# LCM32F039 register map
File version: 1.0
CPU: CM0 r1p0, little endian, MPU, no FPU, 3 interrupt priority bits
Registers are 32-bit, read-write, reset 0x0 unless marked. A register's access mark holds for its fields unless they carry their own. Offsets are from the block's base; [hi:lo] are bit positions; {n}, {i} and the like mark numbered series.

## EXTI
Base 0x40011000
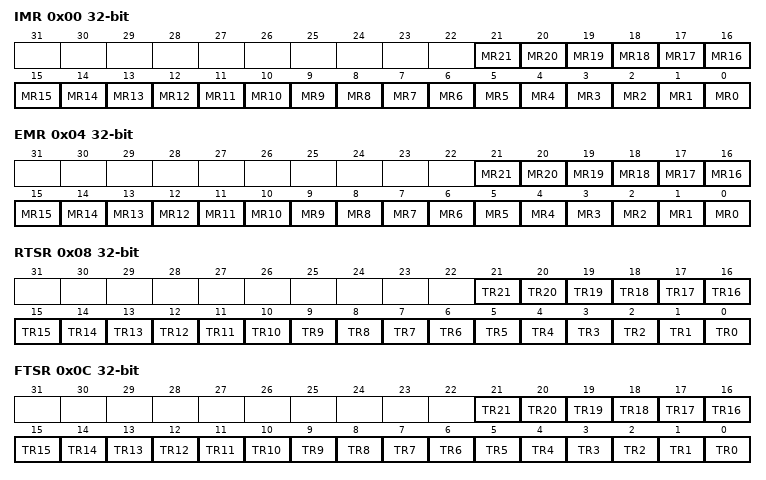
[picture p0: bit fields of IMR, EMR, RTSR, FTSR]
0x00 IMR — EXTI interrupt mask register
  [n] MR{n} (n=0..21) — Interrupt mask on external/internal line x
0x04 EMR — EXTI event mask register
  [n] MR{n} (n=0..21) — Event mask on external/internal line x
0x08 RTSR
  [n] TR{n} (n=0..21)
0x0C FTSR
  [n] TR{n} (n=0..21)
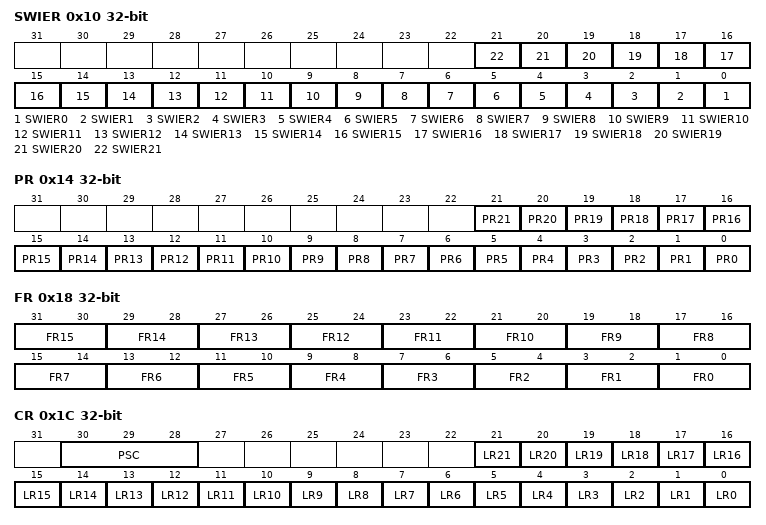
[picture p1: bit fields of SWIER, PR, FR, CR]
0x10 SWIER
  [n] SWIER{n} (n=0..21)
0x14 PR
  [n] PR{n} (n=0..21)
0x18 FR
  [2n+1:2n] FR{n} (n=0..15)
0x1C CR
  [30:28] PSC, [n] LR{n} (n=0..21)

## ANACTRL — Analog system controler.
Base 0x40017C00
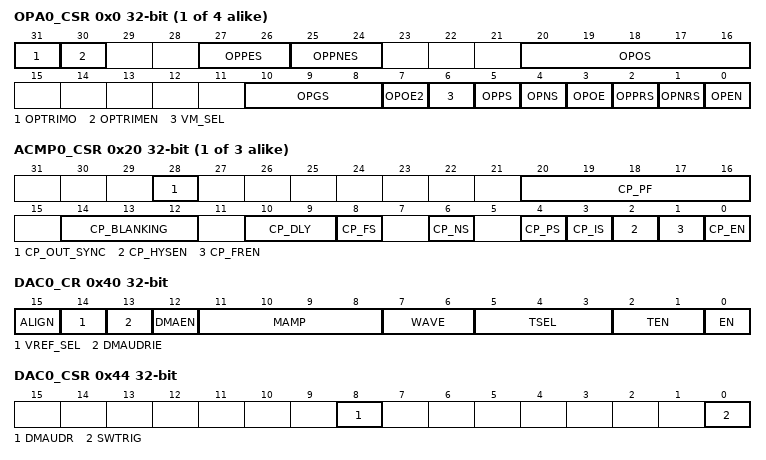
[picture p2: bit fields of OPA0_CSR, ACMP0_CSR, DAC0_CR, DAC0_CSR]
{0x0+4i} OPA{i}_CSR (i=0..3)
  [31] OPTRIMO, [30] OPTRIMEN, [27:26] OPPES, [25:24] OPPNES, [20:16] OPOS, [10:8] OPGS, [7] OPOE2, [6] VM_SEL, [5] OPPS, [4] OPNS, [3] OPOE, [2] OPPRS, [1] OPNRS, [0] OPEN
{0x20+4i} ACMP{i}_CSR (i=0..2)
  [28] CP_OUT_SYNC, [20:16] CP_PF, [14:12] CP_BLANKING, [10:9] CP_DLY, [8] CP_FS, [6] CP_NS, [4] CP_PS, [3] CP_IS, [2] CP_HYSEN, [1] CP_FREN, [0] CP_EN
0x40 DAC0_CR
  [15] ALIGN, [14] VREF_SEL, [13] DMAUDRIE, [12] DMAEN, [11:8] MAMP, [7:6] WAVE, [5:3] TSEL, [2:1] TEN, [0] EN
0x44 DAC0_CSR
  [8] DMAUDR, [0] SWTRIG
0x48 DAC0_DHR
  [15:0] DHR
0x4C DAC0_DOR ro
  [15:0] DOR
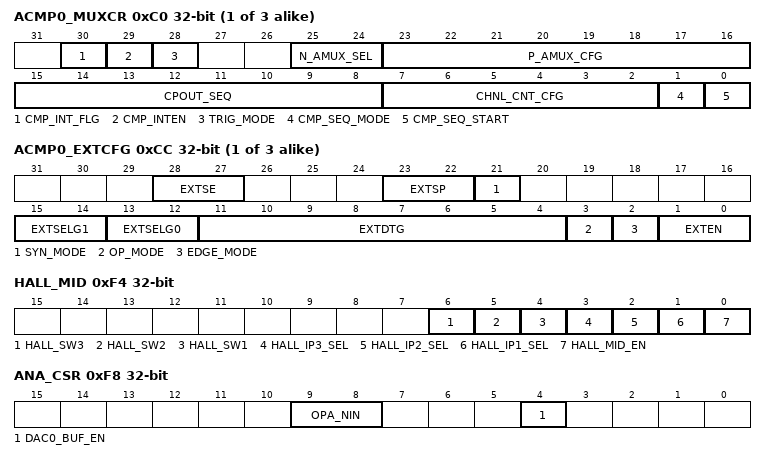
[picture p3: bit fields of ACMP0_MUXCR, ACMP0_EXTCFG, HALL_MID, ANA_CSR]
{0xC0+4i} ACMP{i}_MUXCR (i=0..2)
  [30] CMP_INT_FLG, [29] CMP_INTEN, [28] TRIG_MODE, [25:24] N_AMUX_SEL, [23:16] P_AMUX_CFG, [15:8] CPOUT_SEQ, [7:2] CHNL_CNT_CFG, [1] CMP_SEQ_MODE, [0] CMP_SEQ_START
{0xCC+4i} ACMP{i}_EXTCFG (i=0..2)
  [28:27] EXTSE, [23:22] EXTSP, [21] SYN_MODE, [15:14] EXTSELG1, [13:12] EXTSELG0, [11:4] EXTDTG, [3] OP_MODE, [2] EDGE_MODE, [1:0] EXTEN
0xF4 HALL_MID
  [6] HALL_SW3, [5] HALL_SW2, [4] HALL_SW1, [3] HALL_IP3_SEL, [2] HALL_IP2_SEL, [1] HALL_IP1_SEL, [0] HALL_MID_EN
0xF8 ANA_CSR
  [9:8] OPA_NIN, [4] DAC0_BUF_EN

## CHIPCTRL — chip controler moudle.
Base 0x40017000
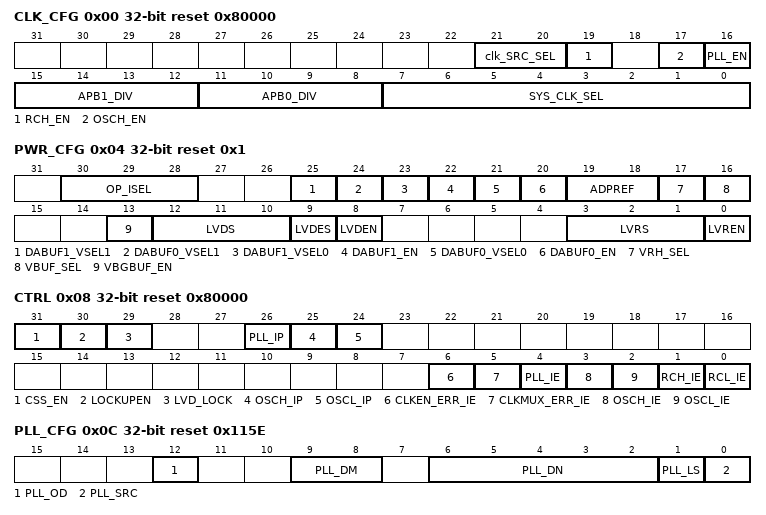
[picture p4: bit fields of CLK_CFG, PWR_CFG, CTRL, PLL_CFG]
0x00 CLK_CFG reset 0x80000
  [21:20] clk_SRC_SEL, [19] RCH_EN, [17] OSCH_EN, [16] PLL_EN, [15:12] APB1_DIV, [11:8] APB0_DIV, [7:0] SYS_CLK_SEL
0x04 PWR_CFG reset 0x1
  [30:28] OP_ISEL, [25] DABUF1_VSEL1, [24] DABUF0_VSEL1, [23] DABUF1_VSEL0, [22] DABUF1_EN, [21] DABUF0_VSEL0, [20] DABUF0_EN, [19:18] ADPREF, [17] VRH_SEL, [16] VBUF_SEL, [13] VBGBUF_EN, [12:10] LVDS, [9] LVDES, [8] LVDEN, [3:1] LVRS, [0] LVREN
0x08 CTRL reset 0x80000
  [31] CSS_EN, [30] LOCKUPEN, [29] LVD_LOCK, [26] PLL_IP, [25] OSCH_IP, [24] OSCL_IP, [6] CLKEN_ERR_IE, [5] CLKMUX_ERR_IE, [4] PLL_IE, [3] OSCH_IE, [2] OSCL_IE, [1] RCH_IE, [0] RCL_IE
0x0C PLL_CFG reset 0x115E
  [12] PLL_OD, [9:8] PLL_DM, [6:2] PLL_DN, [1] PLL_LS, [0] PLL_SRC
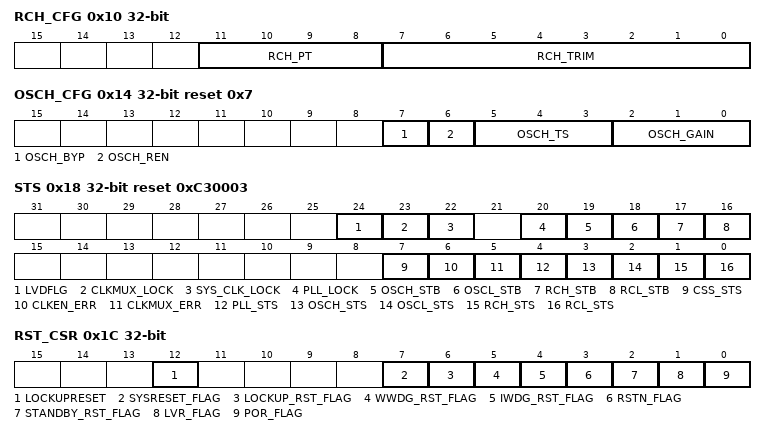
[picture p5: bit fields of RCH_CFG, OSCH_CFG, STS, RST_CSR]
0x10 RCH_CFG
  [11:8] RCH_PT, [7:0] RCH_TRIM
0x14 OSCH_CFG reset 0x7
  [7] OSCH_BYP, [6] OSCH_REN, [5:3] OSCH_TS, [2:0] OSCH_GAIN
0x18 STS reset 0xC30003
  [24] LVDFLG ro, [23] CLKMUX_LOCK ro, [22] SYS_CLK_LOCK ro, [20] PLL_LOCK, [19] OSCH_STB, [18] OSCL_STB, [17] RCH_STB, [16] RCL_STB, [7] CSS_STS, [6] CLKEN_ERR, [5] CLKMUX_ERR, [4] PLL_STS, [3] OSCH_STS, [2] OSCL_STS, [1] RCH_STS, [0] RCL_STS
0x1C RST_CSR
  [12] LOCKUPRESET, [7] SYSRESET_FLAG, [6] LOCKUP_RST_FLAG, [5] WWDG_RST_FLAG, [4] IWDG_RST_FLAG, [3] RSTN_FLAG, [2] STANDBY_RST_FLAG, [1] LVR_FLAG, [0] POR_FLAG
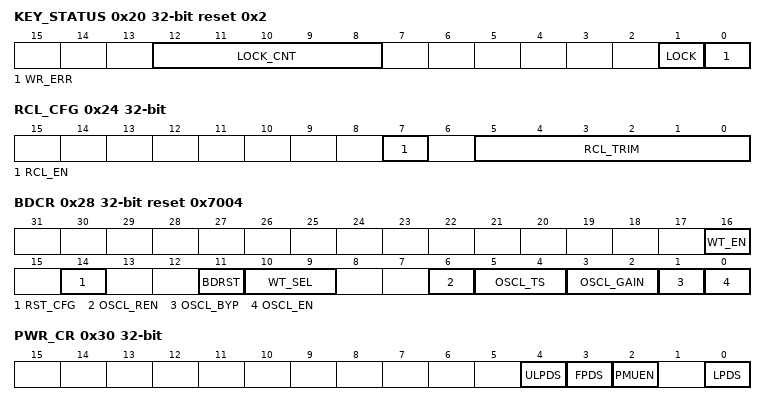
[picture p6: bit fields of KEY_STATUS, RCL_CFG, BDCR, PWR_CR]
0x20 KEY_STATUS reset 0x2
  [12:8] LOCK_CNT, [1] LOCK, [0] WR_ERR
0x24 RCL_CFG
  [7] RCL_EN, [5:0] RCL_TRIM
0x28 BDCR reset 0x7004
  [16] WT_EN, [14] RST_CFG, [11] BDRST, [10:9] WT_SEL, [6] OSCL_REN, [5:4] OSCL_TS, [3:2] OSCL_GAIN, [1] OSCL_BYP, [0] OSCL_EN
0x2C BGR reset 0x20
  [5:0] BGR_TRIM
0x30 PWR_CR
  [4] ULPDS, [3] FPDS, [2] PMUEN, [0] LPDS
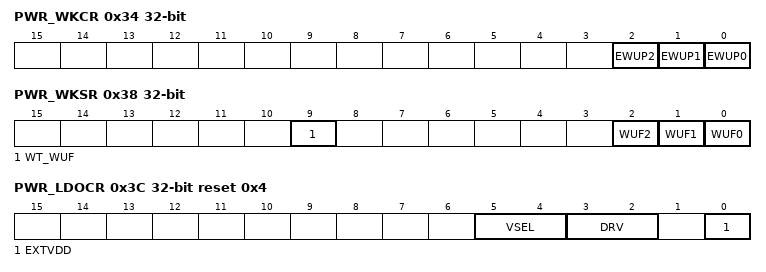
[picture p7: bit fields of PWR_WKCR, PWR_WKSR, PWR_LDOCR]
0x34 PWR_WKCR
  [2] EWUP2, [1] EWUP1, [0] EWUP0
0x38 PWR_WKSR
  [9] WT_WUF, [2] WUF2, [1] WUF1, [0] WUF0
0x3C PWR_LDOCR reset 0x4
  [5:4] VSEL, [3:2] DRV, [0] EXTVDD

## SYSCTRL
Base 0x48007000
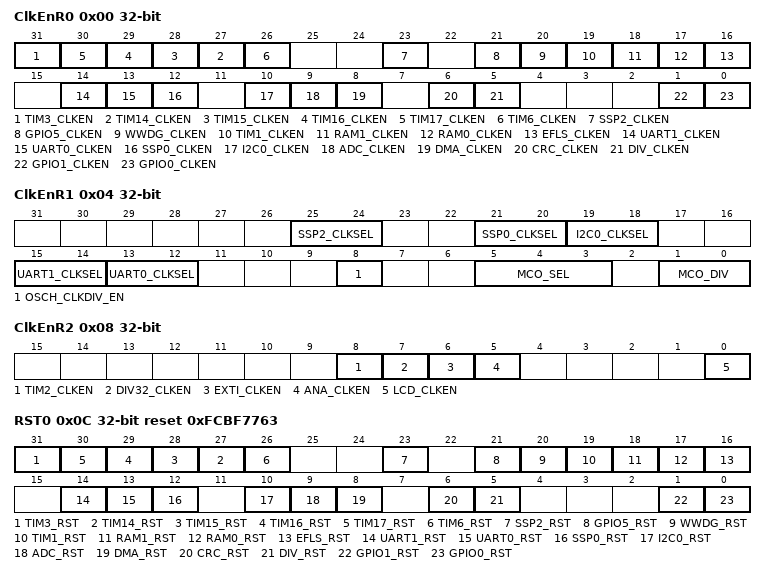
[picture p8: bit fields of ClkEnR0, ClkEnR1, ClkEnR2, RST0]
0x00 ClkEnR0
  [31] TIM3_CLKEN, [n+13] TIM{n}_CLKEN (n=14..17), [26] TIM6_CLKEN, [23] SSP2_CLKEN, [21] GPIO5_CLKEN, [20] WWDG_CLKEN, [19] TIM1_CLKEN, [18] RAM1_CLKEN, [17] RAM0_CLKEN, [16] EFLS_CLKEN, [14] UART1_CLKEN, [13] UART0_CLKEN, [12] SSP0_CLKEN, [10] I2C0_CLKEN, [9] ADC_CLKEN, [8] DMA_CLKEN, [6] CRC_CLKEN, [5] DIV_CLKEN, [1] GPIO1_CLKEN, [0] GPIO0_CLKEN
0x04 ClkEnR1
  [25:24] SSP2_CLKSEL, [21:20] SSP0_CLKSEL, [19:18] I2C0_CLKSEL, [15:14] UART1_CLKSEL, [13:12] UART0_CLKSEL, [8] OSCH_CLKDIV_EN, [5:3] MCO_SEL, [1:0] MCO_DIV
0x08 ClkEnR2
  [8] TIM2_CLKEN, [7] DIV32_CLKEN, [6] EXTI_CLKEN, [5] ANA_CLKEN, [0] LCD_CLKEN
0x0C RST0 reset 0xFCBF7763
  [31] TIM3_RST, [n+13] TIM{n}_RST (n=14..17), [26] TIM6_RST, [23] SSP2_RST, [21] GPIO5_RST, [20] WWDG_RST, [19] TIM1_RST, [18] RAM1_RST, [17] RAM0_RST, [16] EFLS_RST, [14] UART1_RST, [13] UART0_RST, [12] SSP0_RST, [10] I2C0_RST, [9] ADC_RST, [8] DMA_RST, [6] CRC_RST, [5] DIV_RST, [1] GPIO1_RST, [0] GPIO0_RST
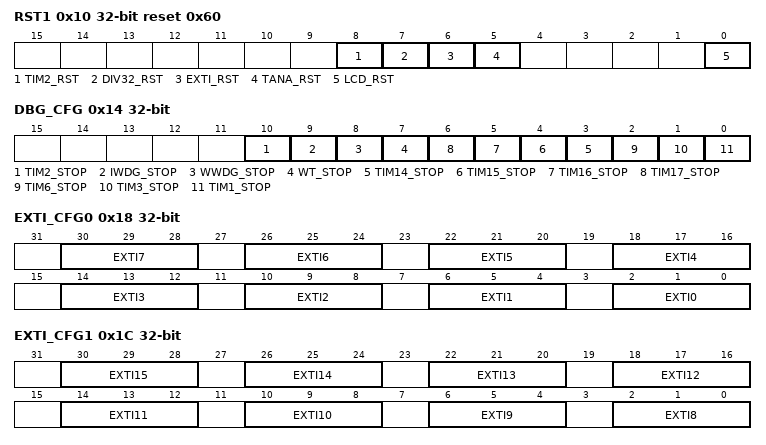
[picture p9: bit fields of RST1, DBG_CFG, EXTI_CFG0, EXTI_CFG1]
0x10 RST1 reset 0x60
  [8] TIM2_RST, [7] DIV32_RST, [6] EXTI_RST, [5] TANA_RST, [0] LCD_RST
0x14 DBG_CFG
  [10] TIM2_STOP, [9] IWDG_STOP, [8] WWDG_STOP, [7] WT_STOP, [n-11] TIM{n}_STOP (n=14..17), [2] TIM6_STOP, [1] TIM3_STOP, [0] TIM1_STOP
0x18 EXTI_CFG0
  [4n+2:4n] EXTI{n} (n=0..7)
0x1C EXTI_CFG1
  [4n-30:4n-32] EXTI{n} (n=8..15)
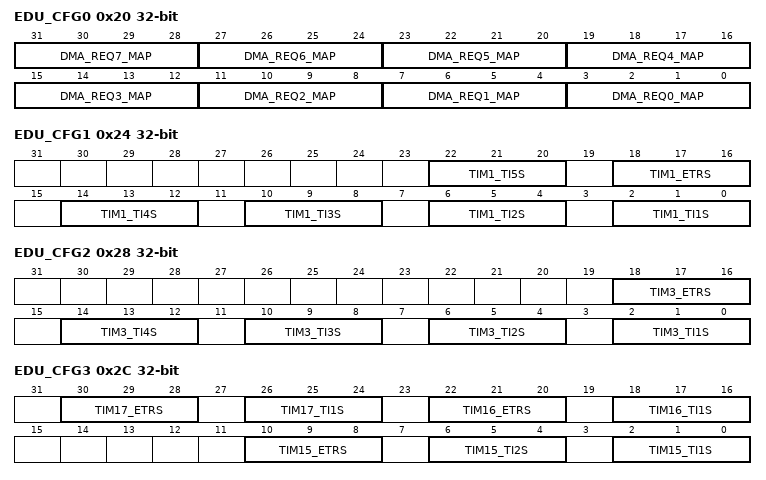
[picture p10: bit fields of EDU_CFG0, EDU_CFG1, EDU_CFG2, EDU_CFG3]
0x20 EDU_CFG0
  [4n+3:4n] DMA_REQ{n}_MAP (n=0..7)
0x24 EDU_CFG1
  [22:20] TIM1_TI5S, [18:16] TIM1_ETRS, [4n-2:4n-4] TIM1_TI{n}S (n=1..4)
0x28 EDU_CFG2
  [18:16] TIM3_ETRS, [4n-2:4n-4] TIM3_TI{n}S (n=1..4)
0x2C EDU_CFG3
  [30:28] TIM17_ETRS, [26:24] TIM17_TI1S, [22:20] TIM16_ETRS, [18:16] TIM16_TI1S, [10:8] TIM15_ETRS, [6:4] TIM15_TI2S, [2:0] TIM15_TI1S
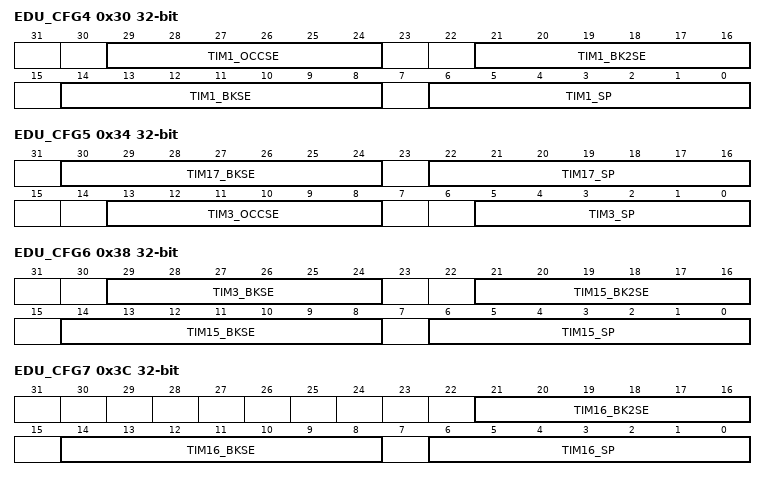
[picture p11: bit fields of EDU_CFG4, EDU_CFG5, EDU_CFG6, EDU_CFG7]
0x30 EDU_CFG4
  [29:24] TIM1_OCCSE, [21:16] TIM1_BK2SE, [14:8] TIM1_BKSE, [6:0] TIM1_SP
0x34 EDU_CFG5
  [30:24] TIM17_BKSE, [22:16] TIM17_SP, [13:8] TIM3_OCCSE, [5:0] TIM3_SP
0x38 EDU_CFG6
  [29:24] TIM3_BKSE, [21:16] TIM15_BK2SE, [14:8] TIM15_BKSE, [6:0] TIM15_SP
0x3C EDU_CFG7
  [21:16] TIM16_BK2SE, [14:8] TIM16_BKSE, [6:0] TIM16_SP
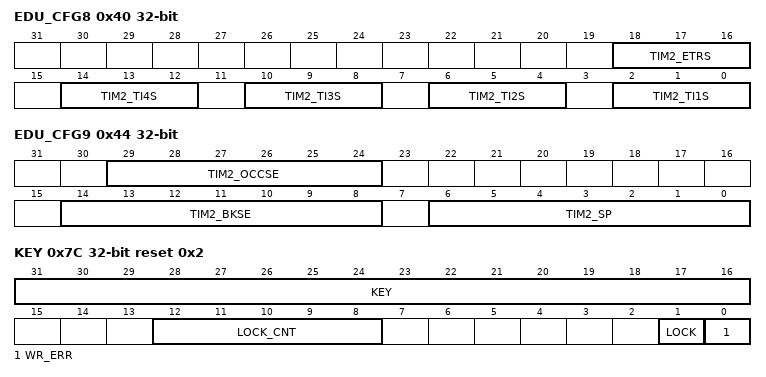
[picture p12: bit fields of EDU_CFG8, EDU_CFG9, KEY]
0x40 EDU_CFG8
  [18:16] TIM2_ETRS, [4n-2:4n-4] TIM2_TI{n}S (n=1..4)
0x44 EDU_CFG9
  [29:24] TIM2_OCCSE, [14:8] TIM2_BKSE, [6:0] TIM2_SP
0x7C KEY reset 0x2
  [31:16] KEY, [12:8] LOCK_CNT, [1] LOCK, [0] WR_ERR

## WT
Base 0x40017800
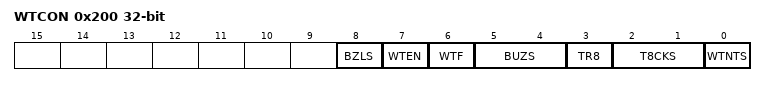
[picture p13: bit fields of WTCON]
0x200 WTCON
  [8] BZLS, [7] WTEN, [6] WTF, [5:4] BUZS, [3] TR8, [2:1] T8CKS, [0] WTNTS
0x204 T8RL
  [7:0] T8

## ADC
Base 0x4001A000
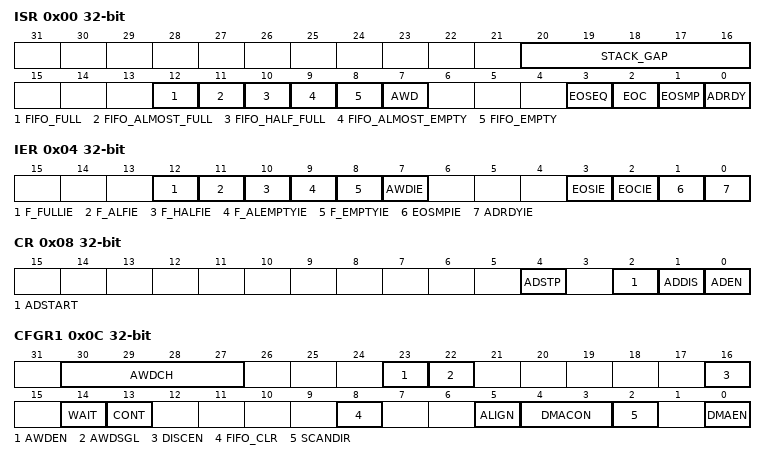
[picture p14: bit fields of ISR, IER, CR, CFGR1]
0x00 ISR
  [20:16] STACK_GAP, [12] FIFO_FULL, [11] FIFO_ALMOST_FULL, [10] FIFO_HALF_FULL, [9] FIFO_ALMOST_EMPTY, [8] FIFO_EMPTY, [7] AWD, [3] EOSEQ, [2] EOC, [1] EOSMP, [0] ADRDY
0x04 IER
  [12] F_FULLIE, [11] F_ALFIE, [10] F_HALFIE, [9] F_ALEMPTYIE, [8] F_EMPTYIE, [7] AWDIE, [3] EOSIE, [2] EOCIE, [1] EOSMPIE, [0] ADRDYIE
0x08 CR
  [4] ADSTP, [2] ADSTART, [1] ADDIS, [0] ADEN
0x0C CFGR1
  [30:27] AWDCH, [23] AWDEN, [22] AWDSGL, [16] DISCEN, [14] WAIT, [13] CONT, [8] FIFO_CLR, [5] ALIGN, [4:3] DMACON, [2] SCANDIR, [0] DMAEN
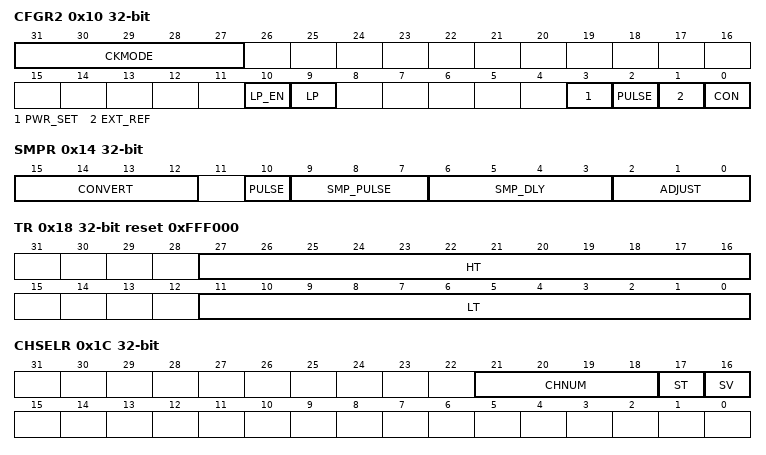
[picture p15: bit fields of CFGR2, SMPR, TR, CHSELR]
0x10 CFGR2
  [31:27] CKMODE, [10] LP_EN, [9] LP, [3] PWR_SET, [2] PULSE, [1] EXT_REF, [0] CON
0x14 SMPR
  [15:12] CONVERT, [10] PULSE, [9:7] SMP_PULSE, [6:3] SMP_DLY, [2:0] ADJUST
0x18 TR reset 0xFFF000
  [27:16] HT, [11:0] LT
0x1C CHSELR
  [21:18] CHNUM, [17] ST, [16] SV
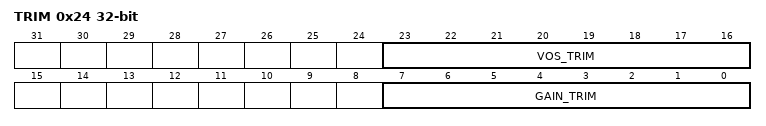
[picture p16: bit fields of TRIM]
0x24 TRIM
  [23:16] VOS_TRIM, [7:0] GAIN_TRIM
0x28 EXTCFG
  [31:27] EXTSE, [26:22] EXTSP, [2n+13:2n+12] EXTSELG{n} (n=0..4), [11:4] EXTDTG, [3] OP_MODE, [2] EDEG_MODE, [1:0] EXTEN
0x2C TESTCFG
  [14] PD_ADC, [13] PD_REF, [12] PD_SH2, [11] PD_SH1, [10] RMD, [9] RTA, [8:6] RT, [5:2] RI, [1] TT, [0] TEST
0x30 CASR
  [4n+3:4n] CH{n} (n=0..7)
0x34 CBSR
  [4n-29:4n-32] CH{n} (n=8..15)
0x38 JCR
  [21] J2TRIG, [20:17] J2CHSEL, [16] J2EN, [5] J1TRIG, [4:1] J1CHSEL, [0] J1EN
0x3C JDR
  [31:16] J2DATA, [15:0] J1DATA
{0x40+4i} FIFO{i} (i=0..15)

## IWDG
Base 0x40017400
0x00 KR
  [7:0] KEY
0x04 PR
  [2:0] PR
0x08 RLR
  [11:0] RLR
0x0C SR
  [2] WVU, [1] RVU, [0] PVU
0x10 WINR
  [11:0] WIN

## DIV
Base 0x48014000
0x00 CTRL — divider Control register
  [25] DIV0_INTREN, [24] DIV0, [8] DIV32, [4] DIV_B_WRITED, [3] DIV_AHI_WRITED, [2] DIV_ALO_WRITED, [1] DIV_IN_PROCEEED, [0] DIV_RST
0x04 ALO — divider Low register
  [31:0] DIV_ALO
0x08 AHI — divider High register
  [31:0] DIV_AHI
0x0C B — divider register
  [31:0] DIV_B
0x10 QUOTLO — divider quotient low register
  [31:0] DIV_QUOTLO
0x14 QUOTHI — divider quotient high register
  [31:0] DIV_QUOTHI
0x18 REM — devider remainde register
  [31:0] DIV_REM

## CRC
Base 0x48011000
0x00 CTRL — Cyclic Redundancy Check Control register
  [25:24] CRC_GPS — CRC Polynomial selection
  [18:17] CRC_SWAP — CRC Byte order conversion of data to be checked
  [16] CRC_LMS — CRC Large Mall Select
  [15] CRC_IVN_EN — CRC Operation result byte size end selection
  [9:8] CRC_BYTE
  [2] CRC_VALID — CRC Valid result flag data
  [1] CRC_SRST — CRC Start Reset
  [0] CRC_SRSTALL — CRC Reset
0x04 DATA — Cyclic Redundancy Check Data register
  [31:0] data — CRC Valid Data
0x08 RESULT — Cyclic Redundancy Check Result register
  [31:0] data — CRC Valid Data
